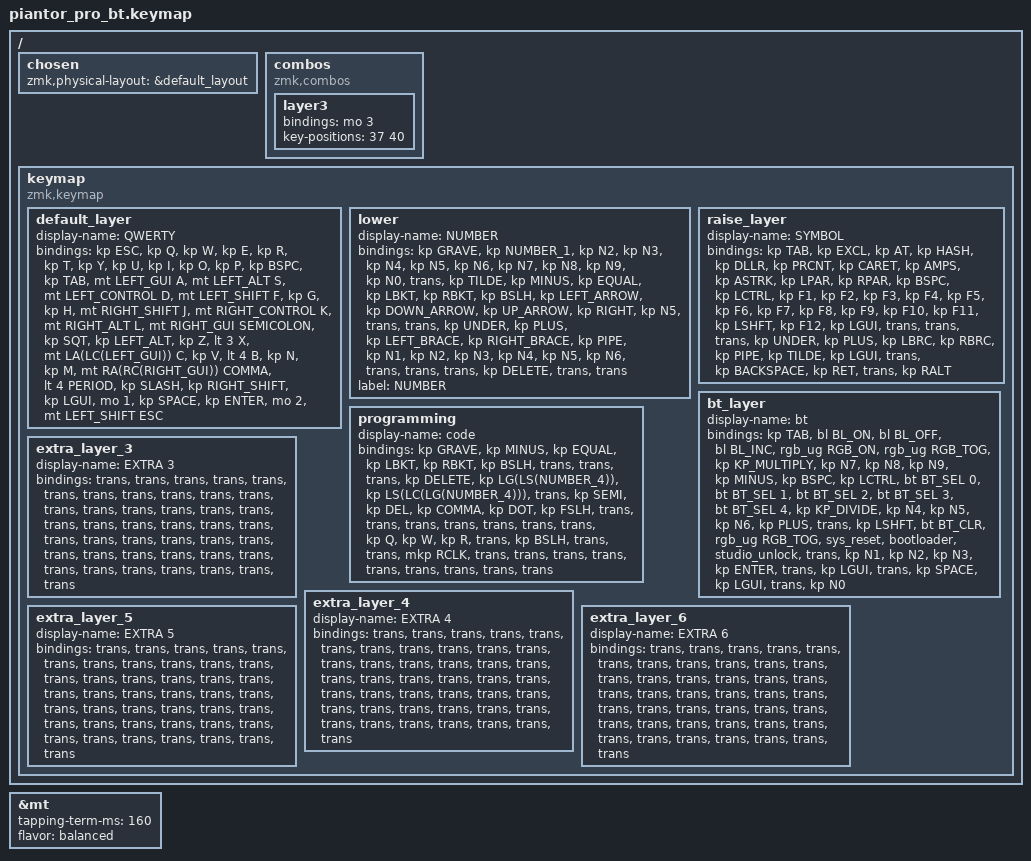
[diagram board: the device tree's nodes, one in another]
/*
 * Copyright (c) 2020 The ZMK Contributors
 *
 * SPDX-License-Identifier: MIT
 */

#include <behaviors.dtsi>
#include <dt-bindings/zmk/backlight.h>
#include <dt-bindings/zmk/bt.h>
#include <dt-bindings/zmk/keys.h>
#include <dt-bindings/zmk/pointing.h>
#include <dt-bindings/zmk/rgb.h>

&mt {
    tapping-term-ms = <160>;
    flavor = "balanced";
};

/ {
    chosen { zmk,physical-layout = &default_layout; };
};

/ {
    combos {
        compatible = "zmk,combos";

        layer3 {
            bindings = <&mo 3>;
            key-positions = <37 40>;
        };
    };

    keymap {
        compatible = "zmk,keymap";

        default_layer {
            display-name = "QWERTY";

            // --------------------------------------------------------------------------------
            // |  TAB |  Q  |  W  |  E  |  R  |  T  |  Y  |  U   |  I  |  O  |  P  | BSPC |
            // | CTRL |  A  |  S  |  D  |  F  |  G  |  H  |  J   |  K  |  L  |  ;  |  '   |
            // | SHFT |  Z  |  X  |  C  |  V  |  B  |  N  |  M   |  ,  |  .  |  /  | ESC  |
            //                    | GUI | LWR | SPC | ENT | RSE  | ALT |

            bindings = <
&kp ESC  &kp Q  &kp W  &kp E  &kp R  &kp T  &kp Y  &kp U  &kp I  &kp O  &kp P  &kp BSPC  &kp TAB  &mt LEFT_GUI A  &mt LEFT_ALT S  &mt LEFT_CONTROL D  &mt LEFT_SHIFT F  &kp G  &kp H  &mt RIGHT_SHIFT J  &mt RIGHT_CONTROL K  &mt RIGHT_ALT L  &mt RIGHT_GUI SEMICOLON  &kp SQT  &kp LEFT_ALT  &kp Z  &lt 3 X  &mt LA(LC(LEFT_GUI)) C  &kp V  &lt 4 B  &kp N  &kp M  &mt RA(RC(RIGHT_GUI)) COMMA  &lt 4 PERIOD  &kp SLASH  &kp RIGHT_SHIFT  &kp LGUI  &mo 1  &kp SPACE  &kp ENTER  &mo 2  &mt LEFT_SHIFT ESC
            >;
        };

        lower {
            display-name = "NUMBER";
            bindings = <
&kp GRAVE  &kp NUMBER_1  &kp N2  &kp N3  &kp N4  &kp N5  &kp N6  &kp N7  &kp N8  &kp N9  &kp N0  &trans  &kp TILDE  &kp MINUS  &kp EQUAL  &kp LBKT  &kp RBKT  &kp BSLH  &kp LEFT_ARROW  &kp DOWN_ARROW  &kp UP_ARROW  &kp RIGHT  &kp N5  &trans  &trans  &kp UNDER  &kp PLUS  &kp LEFT_BRACE  &kp RIGHT_BRACE  &kp PIPE  &kp N1  &kp N2  &kp N3  &kp N4  &kp N5  &kp N6  &trans  &trans  &trans  &kp DELETE  &trans  &trans
            >;

            label = "NUMBER";
        };

        raise_layer {
            display-name = "SYMBOL";

            // -----------------------------------------------------------------------------------------
            // |  TAB |  !  |  @  |  #  |  $  |  %  |  ^  |  &  |  *  |  (  |  )  | BSPC |
            // | CTRL |     |     |     |     |     |  -  |  =  |  [  |  ]  |  \  |  `   |
            // | SHFT |     |     |     |     |     |  _  |  +  |  {  |  }  | "|" |  ~   |
            //                    | GUI |     | SPC | ENT |     | ALT |

            bindings = <
&kp TAB  &kp EXCL  &kp AT  &kp HASH  &kp DLLR  &kp PRCNT  &kp CARET  &kp AMPS  &kp ASTRK  &kp LPAR  &kp RPAR  &kp BSPC  &kp LCTRL  &kp F1  &kp F2  &kp F3  &kp F4  &kp F5  &kp F6  &kp F7  &kp F8  &kp F9  &kp F10  &kp F11  &kp LSHFT  &kp F12  &kp LGUI  &trans  &trans  &trans  &kp UNDER  &kp PLUS  &kp LBRC  &kp RBRC  &kp PIPE  &kp TILDE  &kp LGUI  &trans  &kp BACKSPACE  &kp RET  &trans  &kp RALT
            >;
        };

        bt_layer {
            display-name = "bt";

            // -----------------------------------------------------------------------------------------
            // |  TAB |  1  |  2  |  3  |  4  |  5    |  6  |  7  |  8  |  9  |  0  | BSPC |
            // | CTRL | BT1 | BT2 | BT3 | BT4 | BT5   | LFT | DWN |  UP | RGT |     |      |
            // | SHFT | BTCR| RGB | RST | BOOT| Unlock|     |     |     |     |     |      |
            //                    | GUI |     | SPC   | ENT |     | ALT |

            bindings = <
&kp TAB  &bl BL_ON  &bl BL_OFF  &bl BL_INC  &rgb_ug RGB_ON  &rgb_ug RGB_TOG  &kp KP_MULTIPLY  &kp N7  &kp N8  &kp N9  &kp MINUS  &kp BSPC  &kp LCTRL  &bt BT_SEL 0  &bt BT_SEL 1  &bt BT_SEL 2  &bt BT_SEL 3  &bt BT_SEL 4  &kp KP_DIVIDE  &kp N4  &kp N5  &kp N6  &kp PLUS  &trans  &kp LSHFT  &bt BT_CLR  &rgb_ug RGB_TOG  &sys_reset  &bootloader  &studio_unlock  &trans  &kp N1  &kp N2  &kp N3  &kp ENTER  &trans  &kp LGUI  &trans  &kp SPACE  &kp LGUI  &trans  &kp N0
            >;
        };

        programming {
            display-name = "code";
            bindings = <
&kp GRAVE  &kp MINUS  &kp EQUAL  &kp LBKT  &kp RBKT  &kp BSLH  &trans  &trans  &trans  &kp DELETE  &kp LG(LS(NUMBER_4))  &kp LS(LC(LG(NUMBER_4)))  &trans  &kp SEMI  &kp DEL  &kp COMMA  &kp DOT  &kp FSLH  &trans  &trans  &trans  &trans  &trans  &trans  &trans  &kp Q  &kp W  &kp R  &trans  &kp BSLH  &trans  &trans  &mkp RCLK  &trans  &trans  &trans  &trans  &trans  &trans  &trans  &trans  &trans
            >;
        };

        extra_layer_3 {
            display-name = "EXTRA 3";
            bindings = <
&trans  &trans  &trans  &trans  &trans  &trans  &trans  &trans  &trans  &trans  &trans  &trans  &trans  &trans  &trans  &trans  &trans  &trans  &trans  &trans  &trans  &trans  &trans  &trans  &trans  &trans  &trans  &trans  &trans  &trans  &trans  &trans  &trans  &trans  &trans  &trans  &trans  &trans  &trans  &trans  &trans  &trans
            >;
        };

        extra_layer_4 {
            display-name = "EXTRA 4";
            bindings = <
&trans  &trans  &trans  &trans  &trans  &trans  &trans  &trans  &trans  &trans  &trans  &trans  &trans  &trans  &trans  &trans  &trans  &trans  &trans  &trans  &trans  &trans  &trans  &trans  &trans  &trans  &trans  &trans  &trans  &trans  &trans  &trans  &trans  &trans  &trans  &trans  &trans  &trans  &trans  &trans  &trans  &trans
            >;
        };

        extra_layer_5 {
            display-name = "EXTRA 5";
            bindings = <
&trans  &trans  &trans  &trans  &trans  &trans  &trans  &trans  &trans  &trans  &trans  &trans  &trans  &trans  &trans  &trans  &trans  &trans  &trans  &trans  &trans  &trans  &trans  &trans  &trans  &trans  &trans  &trans  &trans  &trans  &trans  &trans  &trans  &trans  &trans  &trans  &trans  &trans  &trans  &trans  &trans  &trans
            >;
        };

        extra_layer_6 {
            display-name = "EXTRA 6";
            bindings = <
&trans  &trans  &trans  &trans  &trans  &trans  &trans  &trans  &trans  &trans  &trans  &trans  &trans  &trans  &trans  &trans  &trans  &trans  &trans  &trans  &trans  &trans  &trans  &trans  &trans  &trans  &trans  &trans  &trans  &trans  &trans  &trans  &trans  &trans  &trans  &trans  &trans  &trans  &trans  &trans  &trans  &trans
            >;
        };
    };
};
